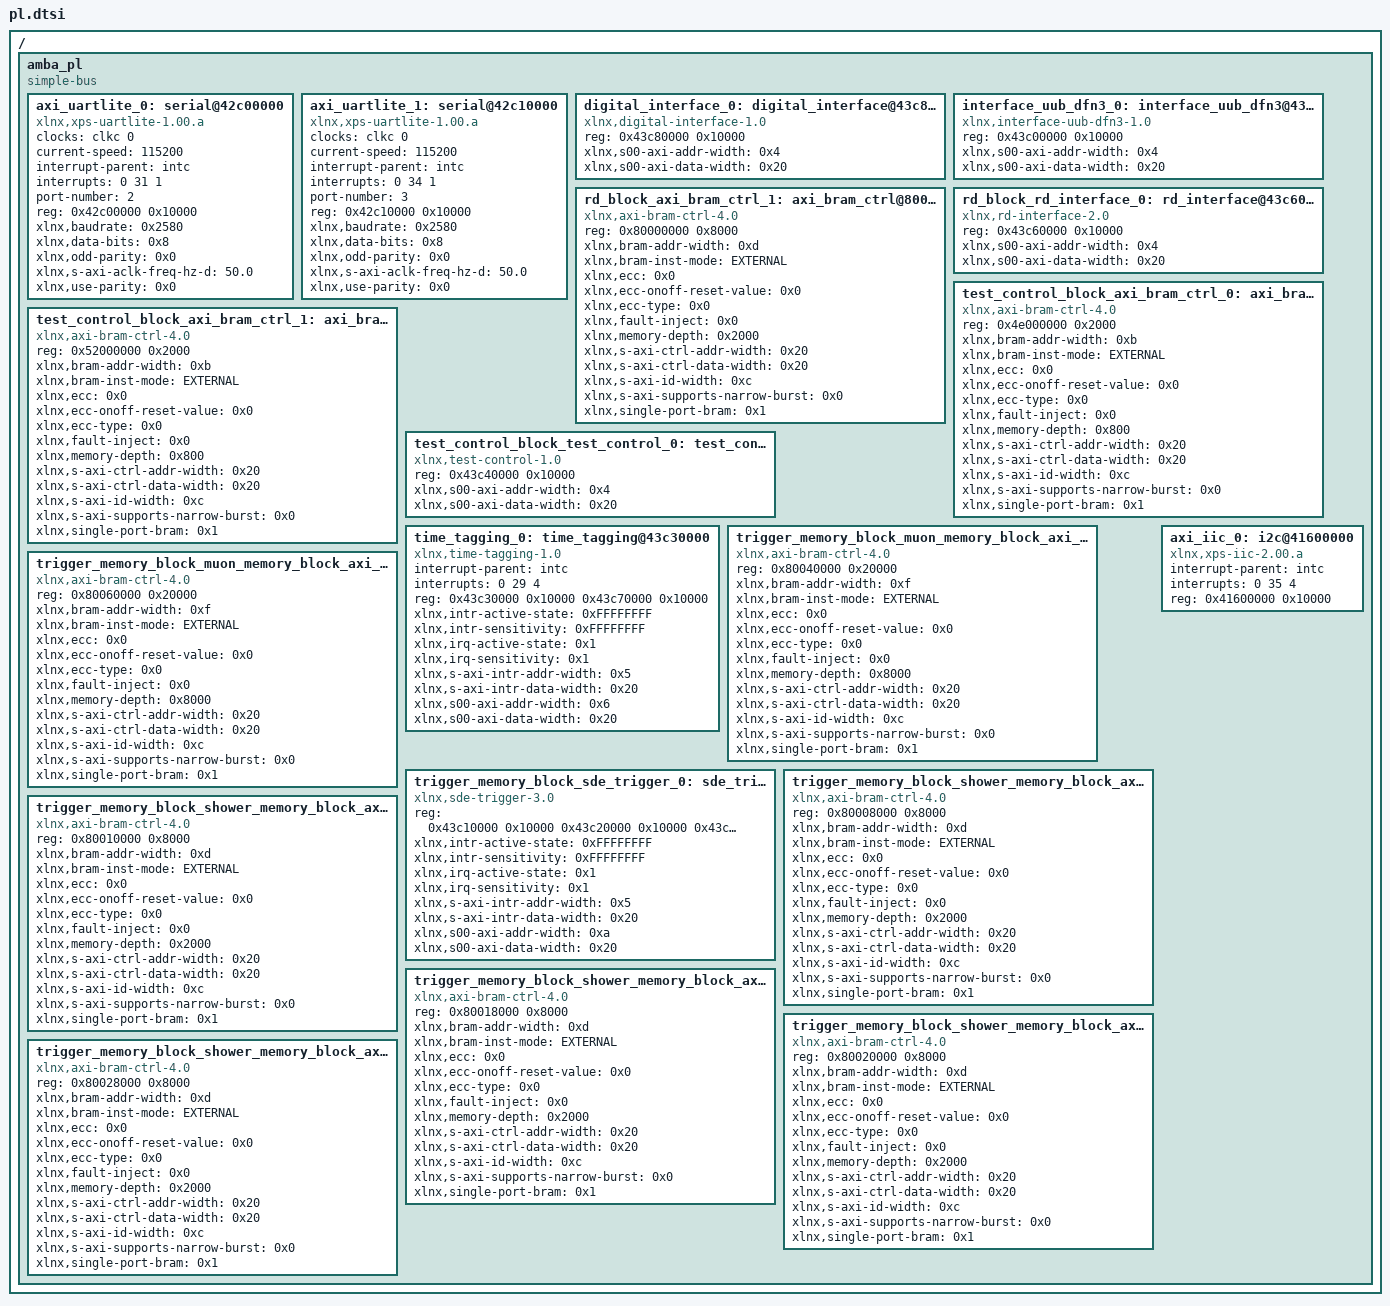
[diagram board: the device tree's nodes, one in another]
/*
 * CAUTION: This file is automatically generated by Xilinx.
 * Version:  
 * Today is: Sun Apr 12 15:03:51 2020
*/


/ {
	amba_pl: amba_pl {
		#address-cells = <1>;
		#size-cells = <1>;
		compatible = "simple-bus";
		ranges ;
		axi_uartlite_0: serial@42c00000 {
			clock-names = "ref_clk";
			clocks = "clkc 0";
			compatible = "xlnx,xps-uartlite-1.00.a";
			current-speed = <115200>;
			device_type = "serial";
			interrupt-parent = <&intc>;
			interrupts = <0 31 1>;
			port-number = <2>;
			reg = <0x42c00000 0x10000>;
			xlnx,baudrate = <0x2580>;
			xlnx,data-bits = <0x8>;
			xlnx,odd-parity = <0x0>;
			xlnx,s-axi-aclk-freq-hz-d = "50.0";
			xlnx,use-parity = <0x0>;
		};
		axi_uartlite_1: serial@42c10000 {
			clock-names = "ref_clk";
			clocks = "clkc 0";
			compatible = "xlnx,xps-uartlite-1.00.a";
			current-speed = <115200>;
			device_type = "serial";
			interrupt-parent = <&intc>;
			interrupts = <0 34 1>;
			port-number = <3>;
			reg = <0x42c10000 0x10000>;
			xlnx,baudrate = <0x2580>;
			xlnx,data-bits = <0x8>;
			xlnx,odd-parity = <0x0>;
			xlnx,s-axi-aclk-freq-hz-d = "50.0";
			xlnx,use-parity = <0x0>;
		};
		digital_interface_0: digital_interface@43c80000 {
			compatible = "xlnx,digital-interface-1.0";
			reg = <0x43c80000 0x10000>;
			xlnx,s00-axi-addr-width = <0x4>;
			xlnx,s00-axi-data-width = <0x20>;
		};
		interface_uub_dfn3_0: interface_uub_dfn3@43c00000 {
			compatible = "xlnx,interface-uub-dfn3-1.0";
			reg = <0x43c00000 0x10000>;
			xlnx,s00-axi-addr-width = <0x4>;
			xlnx,s00-axi-data-width = <0x20>;
		};
		rd_block_axi_bram_ctrl_1: axi_bram_ctrl@80000000 {
			compatible = "xlnx,axi-bram-ctrl-4.0";
			reg = <0x80000000 0x8000>;
			xlnx,bram-addr-width = <0xd>;
			xlnx,bram-inst-mode = "EXTERNAL";
			xlnx,ecc = <0x0>;
			xlnx,ecc-onoff-reset-value = <0x0>;
			xlnx,ecc-type = <0x0>;
			xlnx,fault-inject = <0x0>;
			xlnx,memory-depth = <0x2000>;
			xlnx,s-axi-ctrl-addr-width = <0x20>;
			xlnx,s-axi-ctrl-data-width = <0x20>;
			xlnx,s-axi-id-width = <0xc>;
			xlnx,s-axi-supports-narrow-burst = <0x0>;
			xlnx,single-port-bram = <0x1>;
		};
		rd_block_rd_interface_0: rd_interface@43c60000 {
			compatible = "xlnx,rd-interface-2.0";
			reg = <0x43c60000 0x10000>;
			xlnx,s00-axi-addr-width = <0x4>;
			xlnx,s00-axi-data-width = <0x20>;
		};
		test_control_block_axi_bram_ctrl_0: axi_bram_ctrl@4e000000 {
			compatible = "xlnx,axi-bram-ctrl-4.0";
			reg = <0x4e000000 0x2000>;
			xlnx,bram-addr-width = <0xb>;
			xlnx,bram-inst-mode = "EXTERNAL";
			xlnx,ecc = <0x0>;
			xlnx,ecc-onoff-reset-value = <0x0>;
			xlnx,ecc-type = <0x0>;
			xlnx,fault-inject = <0x0>;
			xlnx,memory-depth = <0x800>;
			xlnx,s-axi-ctrl-addr-width = <0x20>;
			xlnx,s-axi-ctrl-data-width = <0x20>;
			xlnx,s-axi-id-width = <0xc>;
			xlnx,s-axi-supports-narrow-burst = <0x0>;
			xlnx,single-port-bram = <0x1>;
		};
		test_control_block_axi_bram_ctrl_1: axi_bram_ctrl@52000000 {
			compatible = "xlnx,axi-bram-ctrl-4.0";
			reg = <0x52000000 0x2000>;
			xlnx,bram-addr-width = <0xb>;
			xlnx,bram-inst-mode = "EXTERNAL";
			xlnx,ecc = <0x0>;
			xlnx,ecc-onoff-reset-value = <0x0>;
			xlnx,ecc-type = <0x0>;
			xlnx,fault-inject = <0x0>;
			xlnx,memory-depth = <0x800>;
			xlnx,s-axi-ctrl-addr-width = <0x20>;
			xlnx,s-axi-ctrl-data-width = <0x20>;
			xlnx,s-axi-id-width = <0xc>;
			xlnx,s-axi-supports-narrow-burst = <0x0>;
			xlnx,single-port-bram = <0x1>;
		};
		test_control_block_test_control_0: test_control@43c40000 {
			compatible = "xlnx,test-control-1.0";
			reg = <0x43c40000 0x10000>;
			xlnx,s00-axi-addr-width = <0x4>;
			xlnx,s00-axi-data-width = <0x20>;
		};
		time_tagging_0: time_tagging@43c30000 {
			compatible = "xlnx,time-tagging-1.0";
			interrupt-parent = <&intc>;
			interrupts = <0 29 4>;
			reg = <0x43c30000 0x10000 0x43c70000 0x10000>;
			xlnx,intr-active-state = <0xFFFFFFFF>;
			xlnx,intr-sensitivity = <0xFFFFFFFF>;
			xlnx,irq-active-state = <0x1>;
			xlnx,irq-sensitivity = <0x1>;
			xlnx,s-axi-intr-addr-width = <0x5>;
			xlnx,s-axi-intr-data-width = <0x20>;
			xlnx,s00-axi-addr-width = <0x6>;
			xlnx,s00-axi-data-width = <0x20>;
		};
		trigger_memory_block_muon_memory_block_axi_bram_ctrl_0: axi_bram_ctrl@80040000 {
			compatible = "xlnx,axi-bram-ctrl-4.0";
			reg = <0x80040000 0x20000>;
			xlnx,bram-addr-width = <0xf>;
			xlnx,bram-inst-mode = "EXTERNAL";
			xlnx,ecc = <0x0>;
			xlnx,ecc-onoff-reset-value = <0x0>;
			xlnx,ecc-type = <0x0>;
			xlnx,fault-inject = <0x0>;
			xlnx,memory-depth = <0x8000>;
			xlnx,s-axi-ctrl-addr-width = <0x20>;
			xlnx,s-axi-ctrl-data-width = <0x20>;
			xlnx,s-axi-id-width = <0xc>;
			xlnx,s-axi-supports-narrow-burst = <0x0>;
			xlnx,single-port-bram = <0x1>;
		};
		trigger_memory_block_muon_memory_block_axi_bram_ctrl_1: axi_bram_ctrl@80060000 {
			compatible = "xlnx,axi-bram-ctrl-4.0";
			reg = <0x80060000 0x20000>;
			xlnx,bram-addr-width = <0xf>;
			xlnx,bram-inst-mode = "EXTERNAL";
			xlnx,ecc = <0x0>;
			xlnx,ecc-onoff-reset-value = <0x0>;
			xlnx,ecc-type = <0x0>;
			xlnx,fault-inject = <0x0>;
			xlnx,memory-depth = <0x8000>;
			xlnx,s-axi-ctrl-addr-width = <0x20>;
			xlnx,s-axi-ctrl-data-width = <0x20>;
			xlnx,s-axi-id-width = <0xc>;
			xlnx,s-axi-supports-narrow-burst = <0x0>;
			xlnx,single-port-bram = <0x1>;
		};
		trigger_memory_block_sde_trigger_0: sde_trigger@43c10000 {
			compatible = "xlnx,sde-trigger-3.0";
			reg = <0x43c10000 0x10000 0x43c20000 0x10000 0x43c50000 0x10000>;
			xlnx,intr-active-state = <0xFFFFFFFF>;
			xlnx,intr-sensitivity = <0xFFFFFFFF>;
			xlnx,irq-active-state = <0x1>;
			xlnx,irq-sensitivity = <0x1>;
			xlnx,s-axi-intr-addr-width = <0x5>;
			xlnx,s-axi-intr-data-width = <0x20>;
			xlnx,s00-axi-addr-width = <0xa>;
			xlnx,s00-axi-data-width = <0x20>;
		};
		trigger_memory_block_shower_memory_block_axi_bram_ctrl_0: axi_bram_ctrl@80008000 {
			compatible = "xlnx,axi-bram-ctrl-4.0";
			reg = <0x80008000 0x8000>;
			xlnx,bram-addr-width = <0xd>;
			xlnx,bram-inst-mode = "EXTERNAL";
			xlnx,ecc = <0x0>;
			xlnx,ecc-onoff-reset-value = <0x0>;
			xlnx,ecc-type = <0x0>;
			xlnx,fault-inject = <0x0>;
			xlnx,memory-depth = <0x2000>;
			xlnx,s-axi-ctrl-addr-width = <0x20>;
			xlnx,s-axi-ctrl-data-width = <0x20>;
			xlnx,s-axi-id-width = <0xc>;
			xlnx,s-axi-supports-narrow-burst = <0x0>;
			xlnx,single-port-bram = <0x1>;
		};
		trigger_memory_block_shower_memory_block_axi_bram_ctrl_1: axi_bram_ctrl@80010000 {
			compatible = "xlnx,axi-bram-ctrl-4.0";
			reg = <0x80010000 0x8000>;
			xlnx,bram-addr-width = <0xd>;
			xlnx,bram-inst-mode = "EXTERNAL";
			xlnx,ecc = <0x0>;
			xlnx,ecc-onoff-reset-value = <0x0>;
			xlnx,ecc-type = <0x0>;
			xlnx,fault-inject = <0x0>;
			xlnx,memory-depth = <0x2000>;
			xlnx,s-axi-ctrl-addr-width = <0x20>;
			xlnx,s-axi-ctrl-data-width = <0x20>;
			xlnx,s-axi-id-width = <0xc>;
			xlnx,s-axi-supports-narrow-burst = <0x0>;
			xlnx,single-port-bram = <0x1>;
		};
		trigger_memory_block_shower_memory_block_axi_bram_ctrl_2: axi_bram_ctrl@80018000 {
			compatible = "xlnx,axi-bram-ctrl-4.0";
			reg = <0x80018000 0x8000>;
			xlnx,bram-addr-width = <0xd>;
			xlnx,bram-inst-mode = "EXTERNAL";
			xlnx,ecc = <0x0>;
			xlnx,ecc-onoff-reset-value = <0x0>;
			xlnx,ecc-type = <0x0>;
			xlnx,fault-inject = <0x0>;
			xlnx,memory-depth = <0x2000>;
			xlnx,s-axi-ctrl-addr-width = <0x20>;
			xlnx,s-axi-ctrl-data-width = <0x20>;
			xlnx,s-axi-id-width = <0xc>;
			xlnx,s-axi-supports-narrow-burst = <0x0>;
			xlnx,single-port-bram = <0x1>;
		};
		trigger_memory_block_shower_memory_block_axi_bram_ctrl_3: axi_bram_ctrl@80020000 {
			compatible = "xlnx,axi-bram-ctrl-4.0";
			reg = <0x80020000 0x8000>;
			xlnx,bram-addr-width = <0xd>;
			xlnx,bram-inst-mode = "EXTERNAL";
			xlnx,ecc = <0x0>;
			xlnx,ecc-onoff-reset-value = <0x0>;
			xlnx,ecc-type = <0x0>;
			xlnx,fault-inject = <0x0>;
			xlnx,memory-depth = <0x2000>;
			xlnx,s-axi-ctrl-addr-width = <0x20>;
			xlnx,s-axi-ctrl-data-width = <0x20>;
			xlnx,s-axi-id-width = <0xc>;
			xlnx,s-axi-supports-narrow-burst = <0x0>;
			xlnx,single-port-bram = <0x1>;
		};
		trigger_memory_block_shower_memory_block_axi_bram_ctrl_4: axi_bram_ctrl@80028000 {
			compatible = "xlnx,axi-bram-ctrl-4.0";
			reg = <0x80028000 0x8000>;
			xlnx,bram-addr-width = <0xd>;
			xlnx,bram-inst-mode = "EXTERNAL";
			xlnx,ecc = <0x0>;
			xlnx,ecc-onoff-reset-value = <0x0>;
			xlnx,ecc-type = <0x0>;
			xlnx,fault-inject = <0x0>;
			xlnx,memory-depth = <0x2000>;
			xlnx,s-axi-ctrl-addr-width = <0x20>;
			xlnx,s-axi-ctrl-data-width = <0x20>;
			xlnx,s-axi-id-width = <0xc>;
			xlnx,s-axi-supports-narrow-burst = <0x0>;
			xlnx,single-port-bram = <0x1>;
		};
		axi_iic_0: i2c@41600000 {
			#address-cells = <1>;
			#size-cells = <0>;
			compatible = "xlnx,xps-iic-2.00.a";
			interrupt-parent = <&intc>;
			interrupts = <0 35 4>;
			reg = <0x41600000 0x10000>;
		};
	};
};
